AUTOSAR XML (schema 4-2-2)
package /RootP_ASWC_M302
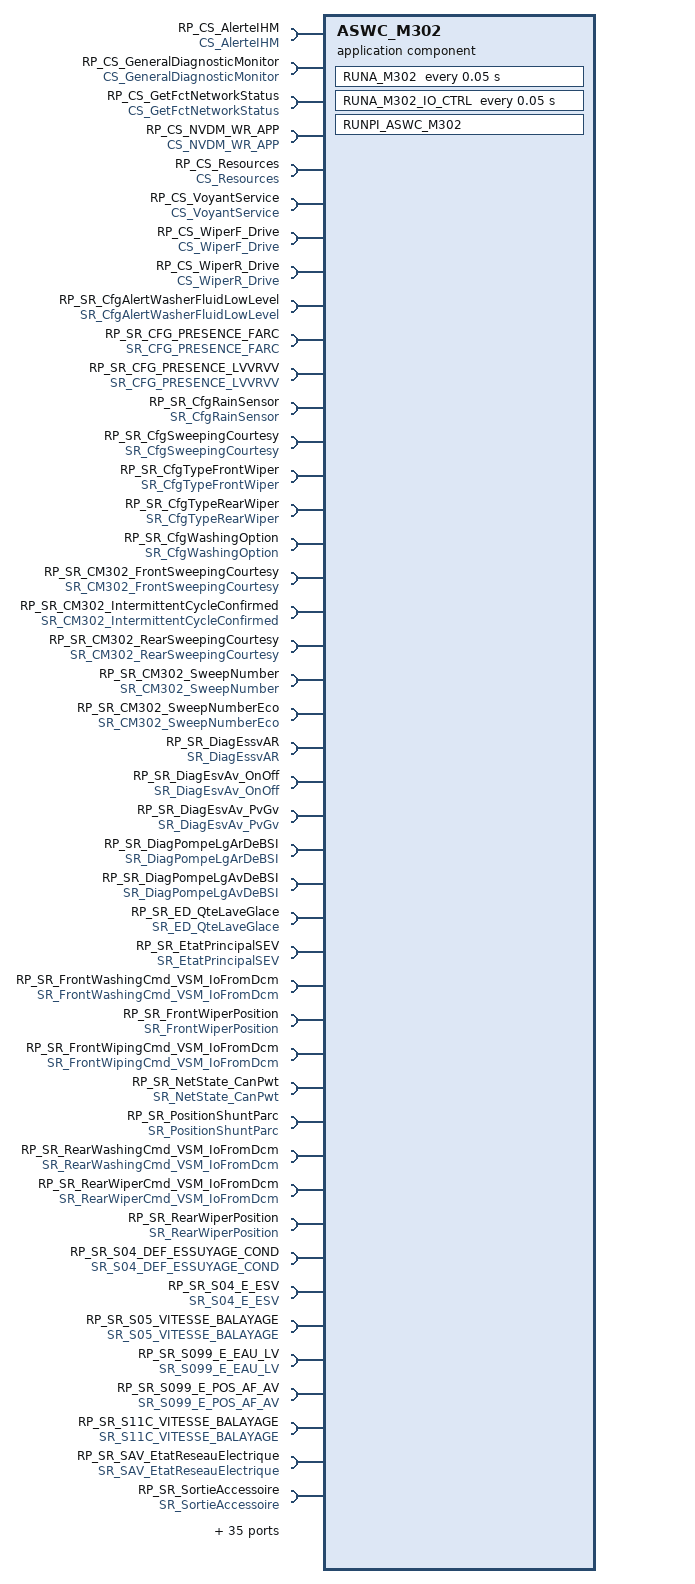
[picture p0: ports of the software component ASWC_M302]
  application sw component type ASWC_M302
    16 x provide/require port:
      PRP_SR_ComAlimEsv: nonqueued-receiver-com-spec{data-element=ComAlimEsv, enable-update=0, handle-data-status=1, handle-never-received=0, init-value=CONST_tLOG_0:0}, provided-required-interface=SR_ComAlimEsv
      PRP_SR_ComAlimEVARDouble: nonqueued-receiver-com-spec{data-element=ComAlimEVARDouble, enable-update=0, handle-data-status=1, handle-never-received=0, init-value=CONST_tLOG_0:0}, provided-required-interface=SR_ComAlimEVARDouble
      PRP_SR_DdeVoySignalisationLgVide: nonqueued-receiver-com-spec{data-element=DdeVoySignalisationLgVide, enable-update=0, handle-data-status=1, handle-never-received=0, init-value=CONST_tLOG_0:0}, provided-required-interface=SR_DdeVoySignalisationLgVide
      PRP_SR_FrontWashingCmd_IO_CTRL: nonqueued-receiver-com-spec{data-element=FrontWashingCmd_IO_CTRL, enable-update=0, handle-data-status=1, handle-never-received=0, init-value=CONST_tLOG_0:0}, provided-required-interface=SR_FrontWashingCmd_IO_CTRL
      PRP_SR_FrontWashingCmd_VSM: nonqueued-receiver-com-spec{data-element=FrontWashingCommand, enable-update=0, handle-data-status=1, handle-never-received=0, init-value=CONST_tLOG_0:0}, provided-required-interface=SR_FrontWashingCmd_VSM
      PRP_SR_FrontWiperCmd_EVAV: provided-required-interface=SR_FrontWiperCmd_EVAV
        required-com-specs:
          data-element=FrontWipingCommand_Pos, enable-update=0, handle-data-status=1, handle-never-received=0, init-value=CONST_FrontWipingCommand_Pos_t_FrontWipingCmdPos_cFrontWipingCmdPos_FixedStop:1
          data-element=FrontWipingCommand_Speed, enable-update=0, handle-data-status=1, handle-never-received=0, init-value=CONST_tBYTE_0:0
      PRP_SR_FrontWiperFailure: provided-required-interface=SR_FrontWiperFailure
        required-com-specs:
          data-element=FrontWiperFailure_ComHS, enable-update=0, handle-data-status=1, handle-never-received=0, init-value=CONST_tLOG_0:0
          data-element=FrontWiperFailure_Maintenance, enable-update=0, handle-data-status=1, handle-never-received=0, init-value=CONST_tLOG_0:0
          data-element=FrontWiperFailure_MotorBlock, enable-update=0, handle-data-status=1, handle-never-received=0, init-value=CONST_tLOG_0:0
      PRP_SR_FrontWiperPositionPark: nonqueued-receiver-com-spec{data-element=FrontWiperPositionPark, enable-update=0, handle-data-status=1, handle-never-received=0, init-value=CONST_tLOG_0:0}, provided-required-interface=SR_FrontWiperPositionPark
      PRP_SR_FrontWiperStatus: provided-required-interface=SR_FrontWiperStatus
        required-com-specs:
          data-element=ContinuousFrontWiping, enable-update=0, handle-data-status=1, handle-never-received=0, init-value=CONST_tLOG_0:0
          data-element=FrontWiperConfirmedStatus, enable-update=0, handle-data-status=1, handle-never-received=0, init-value=CONST_tLOG_0:0
          data-element=FrontWiperRealStatus, enable-update=0, handle-data-status=1, handle-never-received=0, init-value=CONST_FrontWiperRealStatus_t_FrontWiperStatus_cFrontWiperStatus_Stop:0
          data-element=FrontWiperStatus, enable-update=0, handle-data-status=1, handle-never-received=0, init-value=CONST_FrontWiperStatus_t_FrontWiperStatus_cFrontWiperStatus_Stop:0
          data-element=FrontWiperStatusHab, enable-update=0, handle-data-status=1, handle-never-received=0, init-value=CONST_FrontWiperStatusHab_t_FrontWiperStatus_cFrontWiperStatus_Stop:0
      PRP_SR_FrontWipingCmd_IO_CTRL: nonqueued-receiver-com-spec{data-element=FrontWipingCmd_IO_CTRL, enable-update=0, handle-data-status=1, handle-never-received=0, init-value=CONST_FrontWipingCmd_IO_CTRL_t_cWiper_cWiper_Inactive:105}, provided-required-interface=SR_FrontWipingCmd_IO_CTRL
      PRP_SR_FrontWipingCmd_VSM: nonqueued-receiver-com-spec{data-element=FrontWipingCommand, enable-update=0, handle-data-status=1, handle-never-received=0, init-value=CONST_FrontWipingCommand_t_cWiper_cWiper_Inactive:105}, provided-required-interface=SR_FrontWipingCmd_VSM
      PRP_SR_RearWashingCmd_IO_CTRL: nonqueued-receiver-com-spec{data-element=RearWashingCmd_IO_CTRL, enable-update=0, handle-data-status=1, handle-never-received=0, init-value=CONST_tLOG_0:0}, provided-required-interface=SR_RearWashingCmd_IO_CTRL
      PRP_SR_RearWashingCmd_VSM: nonqueued-receiver-com-spec{data-element=RearWashingCommand, enable-update=0, handle-data-status=1, handle-never-received=0, init-value=CONST_tLOG_0:0}, provided-required-interface=SR_RearWashingCmd_VSM
      PRP_SR_RearWiperCmd_VSM: nonqueued-receiver-com-spec{data-element=RearWipingCommand, enable-update=0, handle-data-status=1, handle-never-received=0, init-value=CONST_RearWipingCommand_t_cWiper_cWiper_Inactive:105}, provided-required-interface=SR_RearWiperCmd_VSM
      PRP_SR_RearWiperFailure: nonqueued-receiver-com-spec{data-element=RearWiperFailure_MotorBlock, enable-update=0, handle-data-status=1, handle-never-received=0, init-value=CONST_tLOG_0:0}, provided-required-interface=SR_RearWiperFailure
      PRP_SR_WasherStatus: provided-required-interface=SR_WasherStatus
        required-com-specs:
          data-element=FrontWashingInProgress, enable-update=0, handle-data-status=1, handle-never-received=0, init-value=CONST_tLOG_0:0
          data-element=WasherStatus, enable-update=0, handle-data-status=1, handle-never-received=0, init-value=CONST_tLOG_0:0
    79 x require port:
      RP_CS_AlerteIHM: required-interface=CS_AlerteIHM
      RP_CS_GeneralDiagnosticMonitor: required-interface=CS_GeneralDiagnosticMonitor
      RP_CS_GetFctNetworkStatus: required-interface=CS_GetFctNetworkStatus
      RP_CS_NVDM_WR_APP: required-interface=CS_NVDM_WR_APP
      RP_CS_Resources: required-interface=CS_Resources
      RP_CS_VoyantService: required-interface=CS_VoyantService
      RP_CS_WiperF_Drive: required-interface=CS_WiperF_Drive
      RP_CS_WiperR_Drive: required-interface=CS_WiperR_Drive
      RP_SR_CfgAlertWasherFluidLowLevel: nonqueued-receiver-com-spec{data-element=CfgAlertWasherFluidLowLevel, enable-update=0, handle-data-status=1, handle-never-received=0, init-value=CONST_CfgAlertWasherFluidLowLevel_t_CfgAlertWasherFluid_cCfgAlertWasherFluid_None:0}, required-interface=SR_CfgAlertWasherFluidLowLevel
      RP_SR_CFG_PRESENCE_FARC: nonqueued-receiver-com-spec{data-element=CFG_PRESENCE_FARC, enable-update=0, handle-data-status=1, handle-never-received=0, init-value=CONST_CFG_PRESENCE_FARC_t_cFARC_0_cFARC_absent:0}, required-interface=SR_CFG_PRESENCE_FARC
      RP_SR_CFG_PRESENCE_LVVRVV: nonqueued-receiver-com-spec{data-element=CFG_PRESENCE_LVVRVV, enable-update=0, handle-data-status=1, handle-never-received=0, init-value=CONST_CFG_PRESENCE_LVVRVV_t_cPLR_PRESENCE_cPLR_PRESENCE_AUCUNE:0}, required-interface=SR_CFG_PRESENCE_LVVRVV
      RP_SR_CfgRainSensor: nonqueued-receiver-com-spec{data-element=CfgRainSensor, enable-update=0, handle-data-status=1, handle-never-received=0, init-value=CONST_CfgRainSensor_t_CfgRainSensor_cCfgRainSensor_None:0}, required-interface=SR_CfgRainSensor
      RP_SR_CfgSweepingCourtesy: nonqueued-receiver-com-spec{data-element=CfgSweepingCourtesy, enable-update=0, handle-data-status=1, handle-never-received=0, init-value=CONST_CfgSweepingCourtesy_t_CfgSweepingCourtesy_cCfgSweepingCourtesy_Both:3}, required-interface=SR_CfgSweepingCourtesy
      RP_SR_CfgTypeFrontWiper: nonqueued-receiver-com-spec{data-element=CfgTypeFrontWiper, enable-update=0, handle-data-status=1, handle-never-received=0, init-value=CONST_CfgTypeFrontWiper_t_CfgTypeFrontWiper_cCfgTypeFrontWiper_VSM:0}, required-interface=SR_CfgTypeFrontWiper
      RP_SR_CfgTypeRearWiper: nonqueued-receiver-com-spec{data-element=CfgTypeRearWiper, enable-update=0, handle-data-status=1, handle-never-received=0, init-value=CONST_CfgTypeRearWiper_t_CfgTypeRearWiper_cCfgTypeRearWiper_VSM:1}, required-interface=SR_CfgTypeRearWiper
      RP_SR_CfgWashingOption: nonqueued-receiver-com-spec{data-element=CfgWashingOption, enable-update=0, handle-data-status=1, handle-never-received=0, init-value=CONST_t_CfgWashingOption_0:0}, required-interface=SR_CfgWashingOption
      RP_SR_CM302_FrontSweepingCourtesy: nonqueued-receiver-com-spec{data-element=CM302_FrontSweepingCourtesy, enable-update=0, handle-data-status=1, handle-never-received=0, init-value=CONST_tBYTE_1:1}, required-interface=SR_CM302_FrontSweepingCourtesy
      RP_SR_CM302_IntermittentCycleConfirmed: nonqueued-receiver-com-spec{data-element=CM302_IntermittentCycleConfirmed, enable-update=0, handle-data-status=1, handle-never-received=0, init-value=CONST_tBYTE_3:3}, required-interface=SR_CM302_IntermittentCycleConfirmed
      RP_SR_CM302_RearSweepingCourtesy: nonqueued-receiver-com-spec{data-element=CM302_RearSweepingCourtesy, enable-update=0, handle-data-status=1, handle-never-received=0, init-value=CONST_tBYTE_1:1}, required-interface=SR_CM302_RearSweepingCourtesy
      RP_SR_CM302_SweepNumber: nonqueued-receiver-com-spec{data-element=CM302_SweepNumber, enable-update=0, handle-data-status=1, handle-never-received=0, init-value=CONST_tBYTE_3:3}, required-interface=SR_CM302_SweepNumber
      RP_SR_CM302_SweepNumberEco: nonqueued-receiver-com-spec{data-element=CM302_SweepNumberEco, enable-update=0, handle-data-status=1, handle-never-received=0, init-value=CONST_tBYTE_2:2}, required-interface=SR_CM302_SweepNumberEco
      RP_SR_DiagEssvAR: nonqueued-receiver-com-spec{data-element=DiagEssvAR, enable-update=0, handle-data-status=1, handle-never-received=0, init-value=CONST_DiagEssvAR_t_cSDDiag_cSDDiag_NoInfo:0}, required-interface=SR_DiagEssvAR
      RP_SR_DiagEsvAv_OnOff: nonqueued-receiver-com-spec{data-element=DiagEsvAv_OnOff, enable-update=0, handle-data-status=1, handle-never-received=0, init-value=CONST_DiagEsvAv_OnOff_t_cSDDiag_cSDDiag_Ok:6}, required-interface=SR_DiagEsvAv_OnOff
      RP_SR_DiagEsvAv_PvGv: nonqueued-receiver-com-spec{data-element=DiagEsvAv_PvGv, enable-update=0, handle-data-status=1, handle-never-received=0, init-value=CONST_DiagEsvAv_PvGv_t_cSDDiag_cSDDiag_Ok:6}, required-interface=SR_DiagEsvAv_PvGv
      RP_SR_DiagPompeLgArDeBSI: nonqueued-receiver-com-spec{data-element=DiagPompeLgArDeBSI, enable-update=0, handle-data-status=1, handle-never-received=0, init-value=CONST_DiagPompeLgArDeBSI_t_cSDDiag_cSDDiag_Ok:6}, required-interface=SR_DiagPompeLgArDeBSI
      RP_SR_DiagPompeLgAvDeBSI: nonqueued-receiver-com-spec{data-element=DiagPompeLgAvDeBSI, enable-update=0, handle-data-status=1, handle-never-received=0, init-value=CONST_DiagPompeLgAvDeBSI_t_cSDDiag_cSDDiag_Ok:6}, required-interface=SR_DiagPompeLgAvDeBSI
      RP_SR_ED_QteLaveGlace: nonqueued-receiver-com-spec{data-element=ED_QteLaveGlace, enable-update=0, handle-data-status=1, handle-never-received=0, init-value=CONST_tLOG_1:1}, required-interface=SR_ED_QteLaveGlace
      RP_SR_EtatPrincipalSEV: nonqueued-receiver-com-spec{data-element=EtatPrincipalSEV, enable-update=0, handle-data-status=1, handle-never-received=0, init-value=CONST_EtatPrincipalSEV_t_SEV_SEV_Arret:105}, required-interface=SR_EtatPrincipalSEV
      RP_SR_FrontWashingCmd_VSM_IoFromDcm: nonqueued-receiver-com-spec{data-element=FrontWashingCommand, enable-update=0, handle-data-status=1, handle-never-received=0, init-value=CONST_tLOG_0:0}, required-interface=SR_FrontWashingCmd_VSM_IoFromDcm
      RP_SR_FrontWiperPosition: nonqueued-receiver-com-spec{data-element=FrontWiperPosition, enable-update=0, handle-data-status=1, handle-never-received=0, init-value=CONST_tLOG_1:1}, required-interface=SR_FrontWiperPosition
      RP_SR_FrontWipingCmd_VSM_IoFromDcm: nonqueued-receiver-com-spec{data-element=FrontWipingCommand, enable-update=0, handle-data-status=1, handle-never-received=0, init-value=CONST_FrontWipingCommand_t_cWiper_cWiper_Inactive:105}, required-interface=SR_FrontWipingCmd_VSM_IoFromDcm
      RP_SR_NetState_CanPwt: nonqueued-receiver-com-spec{data-element=NetState_CanPwt, enable-update=0, handle-data-status=1, handle-never-received=0, init-value=CONST_NetState_CanPwt_t_cCANPWT_cPWT_OFF:0}, required-interface=SR_NetState_CanPwt
      RP_SR_PositionShuntParc: nonqueued-receiver-com-spec{data-element=PositionShuntParc, enable-update=0, handle-data-status=1, handle-never-received=0, init-value=CONST_PositionShuntParc_t_cShunt_cShunt_Indetermine:150}, required-interface=SR_PositionShuntParc
      RP_SR_RearWashingCmd_VSM_IoFromDcm: nonqueued-receiver-com-spec{data-element=RearWashingCommand, enable-update=0, handle-data-status=1, handle-never-received=0, init-value=CONST_tLOG_0:0}, required-interface=SR_RearWashingCmd_VSM_IoFromDcm
      RP_SR_RearWiperCmd_VSM_IoFromDcm: nonqueued-receiver-com-spec{data-element=RearWipingCommand, enable-update=0, handle-data-status=1, handle-never-received=0, init-value=CONST_RearWipingCommand_t_cWiper_cWiper_Inactive:105}, required-interface=SR_RearWiperCmd_VSM_IoFromDcm
      RP_SR_RearWiperPosition: nonqueued-receiver-com-spec{data-element=RearWiperPosition, enable-update=0, handle-data-status=1, handle-never-received=0, init-value=CONST_tLOG_1:1}, required-interface=SR_RearWiperPosition
      RP_SR_S04_DEF_ESSUYAGE_COND: nonqueued-receiver-com-spec{data-element=S04_DEF_ESSUYAGE_COND, enable-update=0, handle-data-status=1, handle-never-received=0, init-value=CONST_tLOG_0:0}, required-interface=SR_S04_DEF_ESSUYAGE_COND
      RP_SR_S04_E_ESV: nonqueued-receiver-com-spec{data-element=S04_E_ESV, enable-update=0, handle-data-status=1, handle-never-received=0, init-value=CONST_tBYTE_0:0}, required-interface=SR_S04_E_ESV
      RP_SR_S05_VITESSE_BALAYAGE: nonqueued-receiver-com-spec{data-element=S05_VITESSE_BALAYAGE, enable-update=0, handle-data-status=1, handle-never-received=0, init-value=CONST_tBYTE_0:0}, required-interface=SR_S05_VITESSE_BALAYAGE
      RP_SR_S099_E_EAU_LV: nonqueued-receiver-com-spec{data-element=S099_E_EAU_LV, enable-update=0, handle-data-status=1, handle-never-received=0, init-value=CONST_tLOG_0:0}, required-interface=SR_S099_E_EAU_LV
      RP_SR_S099_E_POS_AF_AV: nonqueued-receiver-com-spec{data-element=S099_E_POS_AF_AV, enable-update=0, handle-data-status=1, handle-never-received=0, init-value=CONST_tLOG_1:1}, required-interface=SR_S099_E_POS_AF_AV
      RP_SR_S11C_VITESSE_BALAYAGE: nonqueued-receiver-com-spec{data-element=S11C_VITESSE_BALAYAGE, enable-update=0, handle-data-status=1, handle-never-received=0, init-value=CONST_tBYTE_0:0}, required-interface=SR_S11C_VITESSE_BALAYAGE
      RP_SR_SAV_EtatReseauElectrique: nonqueued-receiver-com-spec{data-element=SAV_EtatReseauElectrique, enable-update=0, handle-data-status=1, handle-never-received=0, init-value=CONST_SAV_EtatReseauElectrique_t_cGEE_1_cGEE_TI_Nominal:0}, required-interface=SR_SAV_EtatReseauElectrique
      RP_SR_SortieAccessoire: nonqueued-receiver-com-spec{data-element=SortieAccessoire, enable-update=0, handle-data-status=1, handle-never-received=0, init-value=CONST_tLOG_0:0}, required-interface=SR_SortieAccessoire
      RP_SR_TM302_BoostRequest: nonqueued-receiver-com-spec{data-element=TM302_BoostRequest, enable-update=0, handle-data-status=1, handle-never-received=0, init-value=CONST_tWORD_200:200}, required-interface=SR_TM302_BoostRequest
      RP_SR_TM302_ContinuousWiping: nonqueued-receiver-com-spec{data-element=TM302_ContinuousWiping, enable-update=0, handle-data-status=1, handle-never-received=0, init-value=CONST_tWORD_240:240}, required-interface=SR_TM302_ContinuousWiping
      RP_SR_TM302_Filtrage_ACC: nonqueued-receiver-com-spec{data-element=TM302_Filtrage_ACC, enable-update=0, handle-data-status=1, handle-never-received=0, init-value=CONST_tBYTE_20:20}, required-interface=SR_TM302_Filtrage_ACC
      RP_SR_TM302_FrontPumpOffset: nonqueued-receiver-com-spec{data-element=TM302_FrontPumpOffset, enable-update=0, handle-data-status=1, handle-never-received=0, init-value=CONST_tWORD_10:10}, required-interface=SR_TM302_FrontPumpOffset
      RP_SR_TM302_FrontSweepingCourtesy: nonqueued-receiver-com-spec{data-element=TM302_FrontSweepingCourtesy, enable-update=0, handle-data-status=1, handle-never-received=0, init-value=CONST_tBYTE_60:60}, required-interface=SR_TM302_FrontSweepingCourtesy
      RP_SR_TM302_FrontWiperProtection: nonqueued-receiver-com-spec{data-element=TM302_FrontWiperProtection, enable-update=0, handle-data-status=1, handle-never-received=0, init-value=CONST_tBYTE_140:140}, required-interface=SR_TM302_FrontWiperProtection
      RP_SR_TM302_FrontWipingHighSpeedConfirmed: nonqueued-receiver-com-spec{data-element=TM302_FrontWipingHighSpeedConfirmed, enable-update=0, handle-data-status=1, handle-never-received=0, init-value=CONST_tWORD_40:40}, required-interface=SR_TM302_FrontWipingHighSpeedConfirmed
      RP_SR_TM302_FrontWipingIntermittentConfirmed: nonqueued-receiver-com-spec{data-element=TM302_FrontWipingIntermittentConfirmed, enable-update=0, handle-data-status=1, handle-never-received=0, init-value=CONST_tWORD_1200:1200}, required-interface=SR_TM302_FrontWipingIntermittentConfirmed
      RP_SR_TM302_FrontWipingLowSpeedConfirmed: nonqueued-receiver-com-spec{data-element=TM302_FrontWipingLowSpeedConfirmed, enable-update=0, handle-data-status=1, handle-never-received=0, init-value=CONST_tWORD_40:40}, required-interface=SR_TM302_FrontWipingLowSpeedConfirmed
      RP_SR_TM302_FrontWipingOngoing: nonqueued-receiver-com-spec{data-element=TM302_FrontWipingOngoing, enable-update=0, handle-data-status=1, handle-never-received=0, init-value=CONST_tWORD_140:140}, required-interface=SR_TM302_FrontWipingOngoing
      RP_SR_TM302_FrontWipingStopConfirmed: nonqueued-receiver-com-spec{data-element=TM302_FrontWipingStopConfirmed, enable-update=0, handle-data-status=1, handle-never-received=0, init-value=CONST_tWORD_300:300}, required-interface=SR_TM302_FrontWipingStopConfirmed
      RP_SR_TM302_GradualWiping: nonqueued-receiver-com-spec{data-element=TM302_GradualWiping, enable-update=0, handle-data-status=1, handle-never-received=0, init-value=CONST_tBYTE_4:4}, required-interface=SR_TM302_GradualWiping
      RP_SR_TM302_HighSpeedDefect: nonqueued-receiver-com-spec{data-element=TM302_HighSpeedDefect, enable-update=0, handle-data-status=1, handle-never-received=0, init-value=CONST_tBYTE_48:48}, required-interface=SR_TM302_HighSpeedDefect
      RP_SR_TM302_LaunchRearWipingCycle: nonqueued-receiver-com-spec{data-element=TM302_LaunchRearWipingCycle, enable-update=0, handle-data-status=1, handle-never-received=0, init-value=CONST_tBYTE_10:10}, required-interface=SR_TM302_LaunchRearWipingCycle
      RP_SR_TM302_LowSpeedDefect: nonqueued-receiver-com-spec{data-element=TM302_LowSpeedDefect, enable-update=0, handle-data-status=1, handle-never-received=0, init-value=CONST_tBYTE_32:32}, required-interface=SR_TM302_LowSpeedDefect
      RP_SR_TM302_MaintenanceDuration: nonqueued-receiver-com-spec{data-element=TM302_MaintenanceDuration, enable-update=0, handle-data-status=1, handle-never-received=0, init-value=CONST_tBYTE_15:15}, required-interface=SR_TM302_MaintenanceDuration
      RP_SR_TM302_RearPumpOffset: nonqueued-receiver-com-spec{data-element=TM302_RearPumpOffset, enable-update=0, handle-data-status=1, handle-never-received=0, init-value=CONST_tWORD_20:20}, required-interface=SR_TM302_RearPumpOffset
      RP_SR_TM302_RearPumpOffsetSpecific: nonqueued-receiver-com-spec{data-element=TM302_RearPumpOffsetSpecific, enable-update=0, handle-data-status=1, handle-never-received=0, init-value=CONST_tWORD_10:10}, required-interface=SR_TM302_RearPumpOffsetSpecific
      RP_SR_TM302_RearSweepingCourtesy: nonqueued-receiver-com-spec{data-element=TM302_RearSweepingCourtesy, enable-update=0, handle-data-status=1, handle-never-received=0, init-value=CONST_tBYTE_60:60}, required-interface=SR_TM302_RearSweepingCourtesy
      RP_SR_TM302_RearWashingTimeMin: nonqueued-receiver-com-spec{data-element=TM302_RearWashingTimeMin, enable-update=0, handle-data-status=1, handle-never-received=0, init-value=CONST_tWORD_60:60}, required-interface=SR_TM302_RearWashingTimeMin
      RP_SR_TM302_RearWashingTimeMinSpecific: nonqueued-receiver-com-spec{data-element=TM302_RearWashingTimeMinSpecific, enable-update=0, handle-data-status=1, handle-never-received=0, init-value=CONST_tWORD_60:60}, required-interface=SR_TM302_RearWashingTimeMinSpecific
      RP_SR_TM302_RearWiperProtection: nonqueued-receiver-com-spec{data-element=TM302_RearWiperProtection, enable-update=0, handle-data-status=1, handle-never-received=0, init-value=CONST_tBYTE_140:140}, required-interface=SR_TM302_RearWiperProtection
      RP_SR_TM302_ReverseWashPump: nonqueued-receiver-com-spec{data-element=TM302_ReverseWashPump, enable-update=0, handle-data-status=1, handle-never-received=0, init-value=CONST_tWORD_10:10}, required-interface=SR_TM302_ReverseWashPump
      RP_SR_TM302_SweepingOnWashConfirmed: nonqueued-receiver-com-spec{data-element=TM302_SweepingOnWashConfirmed, enable-update=0, handle-data-status=1, handle-never-received=0, init-value=CONST_tWORD_1200:1200}, required-interface=SR_TM302_SweepingOnWashConfirmed
      RP_SR_TM302_ThresholdMaxFrontWash: nonqueued-receiver-com-spec{data-element=TM302_ThresholdMaxFrontWash, enable-update=0, handle-data-status=1, handle-never-received=0, init-value=CONST_tWORD_600:600}, required-interface=SR_TM302_ThresholdMaxFrontWash
      RP_SR_TM302_ThresholdMaxRearWash: nonqueued-receiver-com-spec{data-element=TM302_ThresholdMaxRearWash, enable-update=0, handle-data-status=1, handle-never-received=0, init-value=CONST_tWORD_600:600}, required-interface=SR_TM302_ThresholdMaxRearWash
      RP_SR_TM302_ThresholdMinFrontWash: nonqueued-receiver-com-spec{data-element=TM302_ThresholdMinFrontWash, enable-update=0, handle-data-status=1, handle-never-received=0, init-value=CONST_tWORD_40:40}, required-interface=SR_TM302_ThresholdMinFrontWash
      RP_SR_TM302_ThresholdMinFrontWashEco: nonqueued-receiver-com-spec{data-element=TM302_ThresholdMinFrontWashEco, enable-update=0, handle-data-status=1, handle-never-received=0, init-value=CONST_tWORD_0:0}, required-interface=SR_TM302_ThresholdMinFrontWashEco
      RP_SR_TM302_ThresholdMinSweep: nonqueued-receiver-com-spec{data-element=TM302_ThresholdMinSweep, enable-update=0, handle-data-status=1, handle-never-received=0, init-value=CONST_tBYTE_4:4}, required-interface=SR_TM302_ThresholdMinSweep
      RP_SR_TM310_MinimalTemperatureDefrost: nonqueued-receiver-com-spec{data-element=TM310_MinimalTemperatureDefrost, enable-update=0, handle-data-status=1, handle-never-received=0, init-value=CONST_tBYTE_40:40}, required-interface=SR_TM310_MinimalTemperatureDefrost
      RP_SR_WipingWashingMode: required-interface=SR_WipingWashingMode
        required-com-specs:
          data-element=FrontWipingFrequency, enable-update=0, handle-data-status=1, handle-never-received=0, init-value=CONST_tWORD_0:0
          data-element=NewFrontWashingMode, enable-update=0, handle-data-status=1, handle-never-received=0, init-value=CONST_tLOG_0:0
          data-element=NewFrontWipingMode, enable-update=0, handle-data-status=1, handle-never-received=0, init-value=CONST_tLOG_0:0
          data-element=NewRearWashingMode, enable-update=0, handle-data-status=1, handle-never-received=0, init-value=CONST_tLOG_0:0
          data-element=NewRearWipingMode, enable-update=0, handle-data-status=1, handle-never-received=0, init-value=CONST_tLOG_0:0
          data-element=RearWipingFrequency, enable-update=0, handle-data-status=1, handle-never-received=0, init-value=CONST_tWORD_0:0
      RP_SR_WipingWashingMode_SAV: required-interface=SR_WipingWashingMode_SAV
        required-com-specs:
          data-element=WipingWashingFrontMode, enable-update=0, handle-data-status=1, handle-never-received=0, init-value=CONST_tBYTE_0:0
          data-element=WipingWashingRearMode, enable-update=0, handle-data-status=1, handle-never-received=0, init-value=CONST_tBYTE_0:0
      RP_SR_SURV_HS1_CAR_INFOS_CMF_5F2: nonqueued-receiver-com-spec{data-element=deSurvHs1CarInfosCmf5f2, alive-timeout=0.6, enable-update=0, handle-data-status=1, handle-never-received=0, init-value=CONST_tLOG_0:0}, required-interface=SR_SURV_HS1_CAR_INFOS_CMF_5F2
      RP_SR_SURV_NEA_ETAT_FRONT_WIPING: nonqueued-receiver-com-spec{data-element=deSurvNeaEtatFrontWiping, alive-timeout=0.04, enable-update=0, handle-data-status=1, handle-never-received=0, init-value=CONST_tLOG_0:0}, required-interface=SR_SURV_NEA_ETAT_FRONT_WIPING
      ASWC_M302_MSI: required-interface=AppModeInterface
    behavior IB_ASWC_M302: data-type-mapping=ApplicationModeMapping, handle-termination-and-restart=NO-SUPPORT
      ar-typed-per-instance-memorys:
        27 x data:
          PM302_ContinuousWipingTimer: type=tWORD, init-value=CONST_tWORD_0:0
          PM302_DiagFrontWashing: type=t_cSDDiag, init-value=CONST_PM302_DiagFrontWashing_t_cSDDiag_cSDDiag_NoInfo:0
          PM302_DiagFrontWiping_HsLs: type=t_cSDDiag, init-value=CONST_PM302_DiagFrontWiping_HsLs_t_cSDDiag_cSDDiag_NoInfo:0
          PM302_DiagFrontWiping_OnOff: type=t_cSDDiag, init-value=CONST_PM302_DiagFrontWiping_OnOff_t_cSDDiag_cSDDiag_NoInfo:0
          PM302_DiagRearWashing: type=t_cSDDiag, init-value=CONST_PM302_DiagRearWashing_t_cSDDiag_cSDDiag_NoInfo:0
          PM302_DiagRearWiping: type=t_cSDDiag, init-value=CONST_PM302_DiagRearWiping_t_cSDDiag_cSDDiag_NoInfo:0
          PM302_FrontCourtesyTimer: type=tBYTE, init-value=CONST_tBYTE_0:0
          PM302_FrontSweepingCourtesy: type=tBYTE, init-value=CONST_tBYTE_0:0
          PM302_FrontWiperProtectionCounter: type=tBYTE, init-value=CONST_tBYTE_0:0
          PM302_FrontWiperProtectionTimer: type=tBYTE, init-value=CONST_tBYTE_0:0
          PM302_FrontWipingCmdConfirmedCounter: type=tBYTE, init-value=CONST_tBYTE_0:0
          PM302_FrontWipingCmdConfirmedTimer: type=tWORD, init-value=CONST_tWORD_0:0
          PM302_FrontWipingOnWash: type=tBYTE, init-value=CONST_tBYTE_0:0
          PM302_FrontWipingTimer: type=tWORD, init-value=CONST_tWORD_0:0
          PM302_LastFrontWiperPosition: type=t_WiperPosition, init-value=CONST_PM302_LastFrontWiperPosition_t_WiperPosition_cWiperPosition_Stationnary:0
          PM302_LastRearWiperPosition: type=t_WiperPosition, init-value=CONST_PM302_LastRearWiperPosition_t_WiperPosition_cWiperPosition_Stationnary:0
          PM302_MaintainingNetworkTimer: type=tWORD, init-value=CONST_tWORD_0:0
          PM302_NewWashingRequest: type=tBYTE, init-value=CONST_tBYTE_0:0
          PM302_RearCourtesyTimer: type=tBYTE, init-value=CONST_tBYTE_0:0
          PM302_RearSweepingCourtesy: type=tBYTE, init-value=CONST_tBYTE_0:0
          PM302_RearWiperProtectionTimer: type=tBYTE, init-value=CONST_tBYTE_0:0
          PM302_RearWipingCmdFiltered: type=t_cWiper, init-value=CONST_PM302_RearWipingCmdFiltered_t_cWiper_cWiper_Inactive:105
          PM302_RearWipingOnWash: type=tBYTE, init-value=CONST_tBYTE_0:0
          PM302_RearWipingTimer: type=tWORD, init-value=CONST_tWORD_0:0
          PM302_TotalStopTimer: type=tWORD, init-value=CONST_tWORD_0:0
          PM302_WaitingPlusAcc: type=tBYTE, init-value=CONST_tBYTE_0:0
          PM302_WashingTimer: type=tWORD, init-value=CONST_tWORD_0:0
      timing event RUNA_M302_Cyclic: start-on-event=RUNA_M302, period=0.05
        disabled-mode:
          ASWC_M302_MSI.AppMode.APP_WAKEUP
          ASWC_M302_MSI.AppMode.APP_OFF
          ASWC_M302_MSI.AppMode.APP_SYNC_INIT1
          ASWC_M302_MSI.AppMode.APP_SYNC_INIT2
          ASWC_M302_MSI.AppMode.APP_CONFIG
      timing event RUNA_M302_IO_CTRL_Cyclic: start-on-event=RUNA_M302_IO_CTRL, period=0.05
        disabled-mode:
          ASWC_M302_MSI.AppMode.APP_WAKEUP
          ASWC_M302_MSI.AppMode.APP_OFF
          ASWC_M302_MSI.AppMode.APP_SYNC_INIT1
          ASWC_M302_MSI.AppMode.APP_SYNC_INIT2
          ASWC_M302_MSI.AppMode.APP_CONFIG
      swc mode switch event RUNPI_ASWC_M302_ENTRY: start-on-event=RUNPI_ASWC_M302, activation=ON-ENTRY, mode=ASWC_M302_MSI.AppMode.APP_WAKEUP
      runnable RUNA_M302
        data-read-access:
          89 x access:
            dra_RP_SR_DiagEssvAR_DiagEssvAR: accessed-variable=RP_SR_DiagEssvAR.DiagEssvAR
            dra_RP_SR_DiagEsvAv_OnOff_DiagEsvAv_OnOff: accessed-variable=RP_SR_DiagEsvAv_OnOff.DiagEsvAv_OnOff
            dra_RP_SR_DiagEsvAv_PvGv_DiagEsvAv_PvGv: accessed-variable=RP_SR_DiagEsvAv_PvGv.DiagEsvAv_PvGv
            dra_RP_SR_DiagPompeLgArDeBSI_DiagPompeLgArDeBSI: accessed-variable=RP_SR_DiagPompeLgArDeBSI.DiagPompeLgArDeBSI
            dra_RP_SR_DiagPompeLgAvDeBSI_DiagPompeLgAvDeBSI: accessed-variable=RP_SR_DiagPompeLgAvDeBSI.DiagPompeLgAvDeBSI
            dra_RP_SR_ED_QteLaveGlace_ED_QteLaveGlace: accessed-variable=RP_SR_ED_QteLaveGlace.ED_QteLaveGlace
            dra_RP_SR_EtatPrincipalSEV_EtatPrincipalSEV: accessed-variable=RP_SR_EtatPrincipalSEV.EtatPrincipalSEV
            dra_RP_SR_FrontWiperPosition_FrontWiperPosition: accessed-variable=RP_SR_FrontWiperPosition.FrontWiperPosition
            dra_RP_SR_WipingWashingMode_FrontWipingFrequency: accessed-variable=RP_SR_WipingWashingMode.FrontWipingFrequency
            dra_RP_SR_NetState_CanPwt_NetState_CanPwt: accessed-variable=RP_SR_NetState_CanPwt.NetState_CanPwt
            dra_RP_SR_WipingWashingMode_NewFrontWashingMode: accessed-variable=RP_SR_WipingWashingMode.NewFrontWashingMode
            dra_RP_SR_WipingWashingMode_NewFrontWipingMode: accessed-variable=RP_SR_WipingWashingMode.NewFrontWipingMode
            dra_RP_SR_WipingWashingMode_NewRearWashingMode: accessed-variable=RP_SR_WipingWashingMode.NewRearWashingMode
            dra_RP_SR_WipingWashingMode_NewRearWipingMode: accessed-variable=RP_SR_WipingWashingMode.NewRearWipingMode
            dra_RP_SR_RearWiperPosition_RearWiperPosition: accessed-variable=RP_SR_RearWiperPosition.RearWiperPosition
            dra_RP_SR_WipingWashingMode_RearWipingFrequency: accessed-variable=RP_SR_WipingWashingMode.RearWipingFrequency
            dra_RP_SR_S04_DEF_ESSUYAGE_COND_S04_DEF_ESSUYAGE_COND: accessed-variable=RP_SR_S04_DEF_ESSUYAGE_COND.S04_DEF_ESSUYAGE_COND
            dra_RP_SR_S04_E_ESV_S04_E_ESV: accessed-variable=RP_SR_S04_E_ESV.S04_E_ESV
            dra_RP_SR_S05_VITESSE_BALAYAGE_S05_VITESSE_BALAYAGE: accessed-variable=RP_SR_S05_VITESSE_BALAYAGE.S05_VITESSE_BALAYAGE
            dra_RP_SR_S099_E_EAU_LV_S099_E_EAU_LV: accessed-variable=RP_SR_S099_E_EAU_LV.S099_E_EAU_LV
            dra_RP_SR_S099_E_POS_AF_AV_S099_E_POS_AF_AV: accessed-variable=RP_SR_S099_E_POS_AF_AV.S099_E_POS_AF_AV
            dra_RP_SR_S11C_VITESSE_BALAYAGE_S11C_VITESSE_BALAYAGE: accessed-variable=RP_SR_S11C_VITESSE_BALAYAGE.S11C_VITESSE_BALAYAGE
            dra_RP_SR_SAV_EtatReseauElectrique_SAV_EtatReseauElectrique: accessed-variable=RP_SR_SAV_EtatReseauElectrique.SAV_EtatReseauElectrique
            dra_RP_SR_WipingWashingMode_SAV_WipingWashingFrontMode: accessed-variable=RP_SR_WipingWashingMode_SAV.WipingWashingFrontMode
            dra_RP_SR_WipingWashingMode_SAV_WipingWashingRearMode: accessed-variable=RP_SR_WipingWashingMode_SAV.WipingWashingRearMode
            dra_RP_SR_SURV_HS1_CAR_INFOS_CMF_5F2_deSurvHs1CarInfosCmf5f2: accessed-variable=RP_SR_SURV_HS1_CAR_INFOS_CMF_5F2.deSurvHs1CarInfosCmf5f2
            dra_RP_SR_SURV_NEA_ETAT_FRONT_WIPING_deSurvNeaEtatFrontWiping: accessed-variable=RP_SR_SURV_NEA_ETAT_FRONT_WIPING.deSurvNeaEtatFrontWiping
            dra_RP_SR_CfgAlertWasherFluidLowLevel_CfgAlertWasherFluidLowLevel: accessed-variable=RP_SR_CfgAlertWasherFluidLowLevel.CfgAlertWasherFluidLowLevel
            dra_RP_SR_CFG_PRESENCE_FARC_CFG_PRESENCE_FARC: accessed-variable=RP_SR_CFG_PRESENCE_FARC.CFG_PRESENCE_FARC
            dra_RP_SR_CFG_PRESENCE_LVVRVV_CFG_PRESENCE_LVVRVV: accessed-variable=RP_SR_CFG_PRESENCE_LVVRVV.CFG_PRESENCE_LVVRVV
            dra_RP_SR_CfgRainSensor_CfgRainSensor: accessed-variable=RP_SR_CfgRainSensor.CfgRainSensor
            dra_RP_SR_CfgSweepingCourtesy_CfgSweepingCourtesy: accessed-variable=RP_SR_CfgSweepingCourtesy.CfgSweepingCourtesy
            dra_RP_SR_CfgTypeFrontWiper_CfgTypeFrontWiper: accessed-variable=RP_SR_CfgTypeFrontWiper.CfgTypeFrontWiper
            dra_RP_SR_CfgTypeRearWiper_CfgTypeRearWiper: accessed-variable=RP_SR_CfgTypeRearWiper.CfgTypeRearWiper
            dra_RP_SR_CfgWashingOption_CfgWashingOption: accessed-variable=RP_SR_CfgWashingOption.CfgWashingOption
            dra_RP_SR_CM302_FrontSweepingCourtesy_CM302_FrontSweepingCourtesy: accessed-variable=RP_SR_CM302_FrontSweepingCourtesy.CM302_FrontSweepingCourtesy
            dra_RP_SR_CM302_IntermittentCycleConfirmed_CM302_IntermittentCycleConfirmed: accessed-variable=RP_SR_CM302_IntermittentCycleConfirmed.CM302_IntermittentCycleConfirmed
            dra_RP_SR_CM302_RearSweepingCourtesy_CM302_RearSweepingCourtesy: accessed-variable=RP_SR_CM302_RearSweepingCourtesy.CM302_RearSweepingCourtesy
            dra_RP_SR_CM302_SweepNumber_CM302_SweepNumber: accessed-variable=RP_SR_CM302_SweepNumber.CM302_SweepNumber
            dra_RP_SR_CM302_SweepNumberEco_CM302_SweepNumberEco: accessed-variable=RP_SR_CM302_SweepNumberEco.CM302_SweepNumberEco
            dra_RP_SR_TM302_BoostRequest_TM302_BoostRequest: accessed-variable=RP_SR_TM302_BoostRequest.TM302_BoostRequest
            dra_RP_SR_TM302_ContinuousWiping_TM302_ContinuousWiping: accessed-variable=RP_SR_TM302_ContinuousWiping.TM302_ContinuousWiping
            dra_RP_SR_TM302_FrontPumpOffset_TM302_FrontPumpOffset: accessed-variable=RP_SR_TM302_FrontPumpOffset.TM302_FrontPumpOffset
            dra_RP_SR_TM302_FrontSweepingCourtesy_TM302_FrontSweepingCourtesy: accessed-variable=RP_SR_TM302_FrontSweepingCourtesy.TM302_FrontSweepingCourtesy
            dra_RP_SR_TM302_FrontWiperProtection_TM302_FrontWiperProtection: accessed-variable=RP_SR_TM302_FrontWiperProtection.TM302_FrontWiperProtection
            dra_RP_SR_TM302_FrontWipingHighSpeedConfirmed_TM302_FrontWipingHighSpeedConfirmed: accessed-variable=RP_SR_TM302_FrontWipingHighSpeedConfirmed.TM302_FrontWipingHighSpeedConfirmed
            dra_RP_SR_TM302_FrontWipingIntermittentConfirmed_TM302_FrontWipingIntermittentConfirmed: accessed-variable=RP_SR_TM302_FrontWipingIntermittentConfirmed.TM302_FrontWipingIntermittentConfirmed
            dra_RP_SR_TM302_FrontWipingLowSpeedConfirmed_TM302_FrontWipingLowSpeedConfirmed: accessed-variable=RP_SR_TM302_FrontWipingLowSpeedConfirmed.TM302_FrontWipingLowSpeedConfirmed
            dra_RP_SR_TM302_FrontWipingOngoing_TM302_FrontWipingOngoing: accessed-variable=RP_SR_TM302_FrontWipingOngoing.TM302_FrontWipingOngoing
            dra_RP_SR_TM302_FrontWipingStopConfirmed_TM302_FrontWipingStopConfirmed: accessed-variable=RP_SR_TM302_FrontWipingStopConfirmed.TM302_FrontWipingStopConfirmed
            dra_RP_SR_TM302_GradualWiping_TM302_GradualWiping: accessed-variable=RP_SR_TM302_GradualWiping.TM302_GradualWiping
            dra_RP_SR_TM302_HighSpeedDefect_TM302_HighSpeedDefect: accessed-variable=RP_SR_TM302_HighSpeedDefect.TM302_HighSpeedDefect
            dra_RP_SR_TM302_LaunchRearWipingCycle_TM302_LaunchRearWipingCycle: accessed-variable=RP_SR_TM302_LaunchRearWipingCycle.TM302_LaunchRearWipingCycle
            dra_RP_SR_TM302_LowSpeedDefect_TM302_LowSpeedDefect: accessed-variable=RP_SR_TM302_LowSpeedDefect.TM302_LowSpeedDefect
            dra_RP_SR_TM302_MaintenanceDuration_TM302_MaintenanceDuration: accessed-variable=RP_SR_TM302_MaintenanceDuration.TM302_MaintenanceDuration
            dra_RP_SR_TM302_RearPumpOffset_TM302_RearPumpOffset: accessed-variable=RP_SR_TM302_RearPumpOffset.TM302_RearPumpOffset
            dra_RP_SR_TM302_RearPumpOffsetSpecific_TM302_RearPumpOffsetSpecific: accessed-variable=RP_SR_TM302_RearPumpOffsetSpecific.TM302_RearPumpOffsetSpecific
            dra_RP_SR_TM302_RearSweepingCourtesy_TM302_RearSweepingCourtesy: accessed-variable=RP_SR_TM302_RearSweepingCourtesy.TM302_RearSweepingCourtesy
            dra_RP_SR_TM302_RearWashingTimeMin_TM302_RearWashingTimeMin: accessed-variable=RP_SR_TM302_RearWashingTimeMin.TM302_RearWashingTimeMin
            dra_RP_SR_TM302_RearWashingTimeMinSpecific_TM302_RearWashingTimeMinSpecific: accessed-variable=RP_SR_TM302_RearWashingTimeMinSpecific.TM302_RearWashingTimeMinSpecific
            dra_RP_SR_TM302_RearWiperProtection_TM302_RearWiperProtection: accessed-variable=RP_SR_TM302_RearWiperProtection.TM302_RearWiperProtection
            dra_RP_SR_TM302_ReverseWashPump_TM302_ReverseWashPump: accessed-variable=RP_SR_TM302_ReverseWashPump.TM302_ReverseWashPump
            dra_RP_SR_TM302_SweepingOnWashConfirmed_TM302_SweepingOnWashConfirmed: accessed-variable=RP_SR_TM302_SweepingOnWashConfirmed.TM302_SweepingOnWashConfirmed
            dra_RP_SR_TM302_ThresholdMaxFrontWash_TM302_ThresholdMaxFrontWash: accessed-variable=RP_SR_TM302_ThresholdMaxFrontWash.TM302_ThresholdMaxFrontWash
            dra_RP_SR_TM302_ThresholdMaxRearWash_TM302_ThresholdMaxRearWash: accessed-variable=RP_SR_TM302_ThresholdMaxRearWash.TM302_ThresholdMaxRearWash
            dra_RP_SR_TM302_ThresholdMinFrontWash_TM302_ThresholdMinFrontWash: accessed-variable=RP_SR_TM302_ThresholdMinFrontWash.TM302_ThresholdMinFrontWash
            dra_RP_SR_TM302_ThresholdMinFrontWashEco_TM302_ThresholdMinFrontWashEco: accessed-variable=RP_SR_TM302_ThresholdMinFrontWashEco.TM302_ThresholdMinFrontWashEco
            dra_RP_SR_TM302_ThresholdMinSweep_TM302_ThresholdMinSweep: accessed-variable=RP_SR_TM302_ThresholdMinSweep.TM302_ThresholdMinSweep
            dra_PRP_SR_ComAlimEsv_ComAlimEsv: accessed-variable=PRP_SR_ComAlimEsv.ComAlimEsv
            dra_PRP_SR_ComAlimEVARDouble_ComAlimEVARDouble: accessed-variable=PRP_SR_ComAlimEVARDouble.ComAlimEVARDouble
            dra_PRP_SR_FrontWiperStatus_ContinuousFrontWiping: accessed-variable=PRP_SR_FrontWiperStatus.ContinuousFrontWiping
            dra_PRP_SR_DdeVoySignalisationLgVide_DdeVoySignalisationLgVide: accessed-variable=PRP_SR_DdeVoySignalisationLgVide.DdeVoySignalisationLgVide
            dra_PRP_SR_FrontWashingCmd_VSM_FrontWashingCommand: accessed-variable=PRP_SR_FrontWashingCmd_VSM.FrontWashingCommand
            dra_PRP_SR_WasherStatus_FrontWashingInProgress: accessed-variable=PRP_SR_WasherStatus.FrontWashingInProgress
            dra_PRP_SR_FrontWiperStatus_FrontWiperConfirmedStatus: accessed-variable=PRP_SR_FrontWiperStatus.FrontWiperConfirmedStatus
            dra_PRP_SR_FrontWiperFailure_FrontWiperFailure_ComHS: accessed-variable=PRP_SR_FrontWiperFailure.FrontWiperFailure_ComHS
            dra_PRP_SR_FrontWiperFailure_FrontWiperFailure_Maintenance: accessed-variable=PRP_SR_FrontWiperFailure.FrontWiperFailure_Maintenance
            dra_PRP_SR_FrontWiperFailure_FrontWiperFailure_MotorBlock: accessed-variable=PRP_SR_FrontWiperFailure.FrontWiperFailure_MotorBlock
            dra_PRP_SR_FrontWiperPositionPark_FrontWiperPositionPark: accessed-variable=PRP_SR_FrontWiperPositionPark.FrontWiperPositionPark
            dra_PRP_SR_FrontWiperStatus_FrontWiperRealStatus: accessed-variable=PRP_SR_FrontWiperStatus.FrontWiperRealStatus
            dra_PRP_SR_FrontWiperStatus_FrontWiperStatus: accessed-variable=PRP_SR_FrontWiperStatus.FrontWiperStatus
            dra_PRP_SR_FrontWiperStatus_FrontWiperStatusHab: accessed-variable=PRP_SR_FrontWiperStatus.FrontWiperStatusHab
            dra_PRP_SR_FrontWipingCmd_VSM_FrontWipingCommand: accessed-variable=PRP_SR_FrontWipingCmd_VSM.FrontWipingCommand
            dra_PRP_SR_FrontWiperCmd_EVAV_FrontWipingCommand_Pos: accessed-variable=PRP_SR_FrontWiperCmd_EVAV.FrontWipingCommand_Pos
            dra_PRP_SR_FrontWiperCmd_EVAV_FrontWipingCommand_Speed: accessed-variable=PRP_SR_FrontWiperCmd_EVAV.FrontWipingCommand_Speed
            dra_PRP_SR_RearWashingCmd_VSM_RearWashingCommand: accessed-variable=PRP_SR_RearWashingCmd_VSM.RearWashingCommand
            dra_PRP_SR_RearWiperFailure_RearWiperFailure_MotorBlock: accessed-variable=PRP_SR_RearWiperFailure.RearWiperFailure_MotorBlock
            dra_PRP_SR_RearWiperCmd_VSM_RearWipingCommand: accessed-variable=PRP_SR_RearWiperCmd_VSM.RearWipingCommand
            dra_PRP_SR_WasherStatus_WasherStatus: accessed-variable=PRP_SR_WasherStatus.WasherStatus
        data-write-access:
          21 x access:
            dwa_PRP_SR_ComAlimEsv_ComAlimEsv: accessed-variable=PRP_SR_ComAlimEsv.ComAlimEsv
            dwa_PRP_SR_ComAlimEVARDouble_ComAlimEVARDouble: accessed-variable=PRP_SR_ComAlimEVARDouble.ComAlimEVARDouble
            dwa_PRP_SR_FrontWiperStatus_ContinuousFrontWiping: accessed-variable=PRP_SR_FrontWiperStatus.ContinuousFrontWiping
            dwa_PRP_SR_DdeVoySignalisationLgVide_DdeVoySignalisationLgVide: accessed-variable=PRP_SR_DdeVoySignalisationLgVide.DdeVoySignalisationLgVide
            dwa_PRP_SR_FrontWashingCmd_VSM_FrontWashingCommand: accessed-variable=PRP_SR_FrontWashingCmd_VSM.FrontWashingCommand
            dwa_PRP_SR_WasherStatus_FrontWashingInProgress: accessed-variable=PRP_SR_WasherStatus.FrontWashingInProgress
            dwa_PRP_SR_FrontWiperStatus_FrontWiperConfirmedStatus: accessed-variable=PRP_SR_FrontWiperStatus.FrontWiperConfirmedStatus
            dwa_PRP_SR_FrontWiperFailure_FrontWiperFailure_ComHS: accessed-variable=PRP_SR_FrontWiperFailure.FrontWiperFailure_ComHS
            dwa_PRP_SR_FrontWiperFailure_FrontWiperFailure_Maintenance: accessed-variable=PRP_SR_FrontWiperFailure.FrontWiperFailure_Maintenance
            dwa_PRP_SR_FrontWiperFailure_FrontWiperFailure_MotorBlock: accessed-variable=PRP_SR_FrontWiperFailure.FrontWiperFailure_MotorBlock
            dwa_PRP_SR_FrontWiperPositionPark_FrontWiperPositionPark: accessed-variable=PRP_SR_FrontWiperPositionPark.FrontWiperPositionPark
            dwa_PRP_SR_FrontWiperStatus_FrontWiperRealStatus: accessed-variable=PRP_SR_FrontWiperStatus.FrontWiperRealStatus
            dwa_PRP_SR_FrontWiperStatus_FrontWiperStatus: accessed-variable=PRP_SR_FrontWiperStatus.FrontWiperStatus
            dwa_PRP_SR_FrontWiperStatus_FrontWiperStatusHab: accessed-variable=PRP_SR_FrontWiperStatus.FrontWiperStatusHab
            dwa_PRP_SR_FrontWipingCmd_VSM_FrontWipingCommand: accessed-variable=PRP_SR_FrontWipingCmd_VSM.FrontWipingCommand
            dwa_PRP_SR_FrontWiperCmd_EVAV_FrontWipingCommand_Pos: accessed-variable=PRP_SR_FrontWiperCmd_EVAV.FrontWipingCommand_Pos
            dwa_PRP_SR_FrontWiperCmd_EVAV_FrontWipingCommand_Speed: accessed-variable=PRP_SR_FrontWiperCmd_EVAV.FrontWipingCommand_Speed
            dwa_PRP_SR_RearWashingCmd_VSM_RearWashingCommand: accessed-variable=PRP_SR_RearWashingCmd_VSM.RearWashingCommand
            dwa_PRP_SR_RearWiperFailure_RearWiperFailure_MotorBlock: accessed-variable=PRP_SR_RearWiperFailure.RearWiperFailure_MotorBlock
            dwa_PRP_SR_RearWiperCmd_VSM_RearWipingCommand: accessed-variable=PRP_SR_RearWiperCmd_VSM.RearWipingCommand
            dwa_PRP_SR_WasherStatus_WasherStatus: accessed-variable=PRP_SR_WasherStatus.WasherStatus
        6 x sync call, all with timeout=0:
          sscp_RUNA_M302_RP_CS_AlerteIHM_Cmd: operation=RP_CS_AlerteIHM.Cmd
          sscp_RUNA_M302_RP_CS_GeneralDiagnosticMonitor_SetEventStatus: operation=RP_CS_GeneralDiagnosticMonitor.SetEventStatus
          sscp_RUNA_M302_RP_CS_GetFctNetworkStatus_Get: operation=RP_CS_GetFctNetworkStatus.Get
          sscp_RUNA_M302_RP_CS_NVDM_WR_APP_NvDM_WrApp_Block: operation=RP_CS_NVDM_WR_APP.NvDM_WrApp_Block
          sscp_RUNA_M302_RP_CS_Resources_Request: operation=RP_CS_Resources.Request
          sscp_RUNA_M302_RP_CS_VoyantService_Piloter: operation=RP_CS_VoyantService.Piloter
      runnable RUNA_M302_IO_CTRL
        data-read-access:
          12 x access:
            dra_RP_SR_FrontWashingCmd_VSM_IoFromDcm_FrontWashingCommand: accessed-variable=RP_SR_FrontWashingCmd_VSM_IoFromDcm.FrontWashingCommand
            dra_RP_SR_FrontWipingCmd_VSM_IoFromDcm_FrontWipingCommand: accessed-variable=RP_SR_FrontWipingCmd_VSM_IoFromDcm.FrontWipingCommand
            dra_RP_SR_RearWashingCmd_VSM_IoFromDcm_RearWashingCommand: accessed-variable=RP_SR_RearWashingCmd_VSM_IoFromDcm.RearWashingCommand
            dra_RP_SR_RearWiperCmd_VSM_IoFromDcm_RearWipingCommand: accessed-variable=RP_SR_RearWiperCmd_VSM_IoFromDcm.RearWipingCommand
            dra_RP_SR_PositionShuntParc_PositionShuntParc: accessed-variable=RP_SR_PositionShuntParc.PositionShuntParc
            dra_RP_SR_SortieAccessoire_SortieAccessoire: accessed-variable=RP_SR_SortieAccessoire.SortieAccessoire
            dra_RP_SR_CfgTypeFrontWiper_CfgTypeFrontWiper: accessed-variable=RP_SR_CfgTypeFrontWiper.CfgTypeFrontWiper
            dra_RP_SR_CfgTypeRearWiper_CfgTypeRearWiper: accessed-variable=RP_SR_CfgTypeRearWiper.CfgTypeRearWiper
            dra_RP_SR_TM302_Filtrage_ACC_TM302_Filtrage_ACC: accessed-variable=RP_SR_TM302_Filtrage_ACC.TM302_Filtrage_ACC
            dra_PRP_SR_FrontWashingCmd_IO_CTRL_FrontWashingCmd_IO_CTRL: accessed-variable=PRP_SR_FrontWashingCmd_IO_CTRL.FrontWashingCmd_IO_CTRL
            dra_PRP_SR_FrontWipingCmd_IO_CTRL_FrontWipingCmd_IO_CTRL: accessed-variable=PRP_SR_FrontWipingCmd_IO_CTRL.FrontWipingCmd_IO_CTRL
            dra_PRP_SR_RearWashingCmd_IO_CTRL_RearWashingCmd_IO_CTRL: accessed-variable=PRP_SR_RearWashingCmd_IO_CTRL.RearWashingCmd_IO_CTRL
        data-write-access:
          access dwa_PRP_SR_FrontWashingCmd_IO_CTRL_FrontWashingCmd_IO_CTRL: accessed-variable=PRP_SR_FrontWashingCmd_IO_CTRL.FrontWashingCmd_IO_CTRL
          access dwa_PRP_SR_FrontWipingCmd_IO_CTRL_FrontWipingCmd_IO_CTRL: accessed-variable=PRP_SR_FrontWipingCmd_IO_CTRL.FrontWipingCmd_IO_CTRL
          access dwa_PRP_SR_RearWashingCmd_IO_CTRL_RearWashingCmd_IO_CTRL: accessed-variable=PRP_SR_RearWashingCmd_IO_CTRL.RearWashingCmd_IO_CTRL
        sync call sscp_RUNA_M302_IO_CTRL_RP_CS_WiperF_Drive_OP_SET: operation=RP_CS_WiperF_Drive.OP_SET, timeout=0
        sync call sscp_RUNA_M302_IO_CTRL_RP_CS_WiperR_Drive_OP_SET: operation=RP_CS_WiperR_Drive.OP_SET, timeout=0
      runnable RUNPI_ASWC_M302
package /RootP_Implementation
  swc implementation Implementatation_ASWC_M302: programming-language=C, sw-version=1.0.0, vendor-id=1, behavior=IB_ASWC_M302
    code-descriptors:
      code SRC: artifact-descriptors=autosar-engineering-object={short-label=EngObject, category=SWSRC}
    resource consumption Resources
      memory section CODE: sw-addrmethod=CODE_ASWC_M302
  sw addr method CODE_ASWC_M302: memory-allocation-keyword-policy=ADDR-METHOD-SHORT-NAME-AND-ALIGNMENT, section-type=CODE
